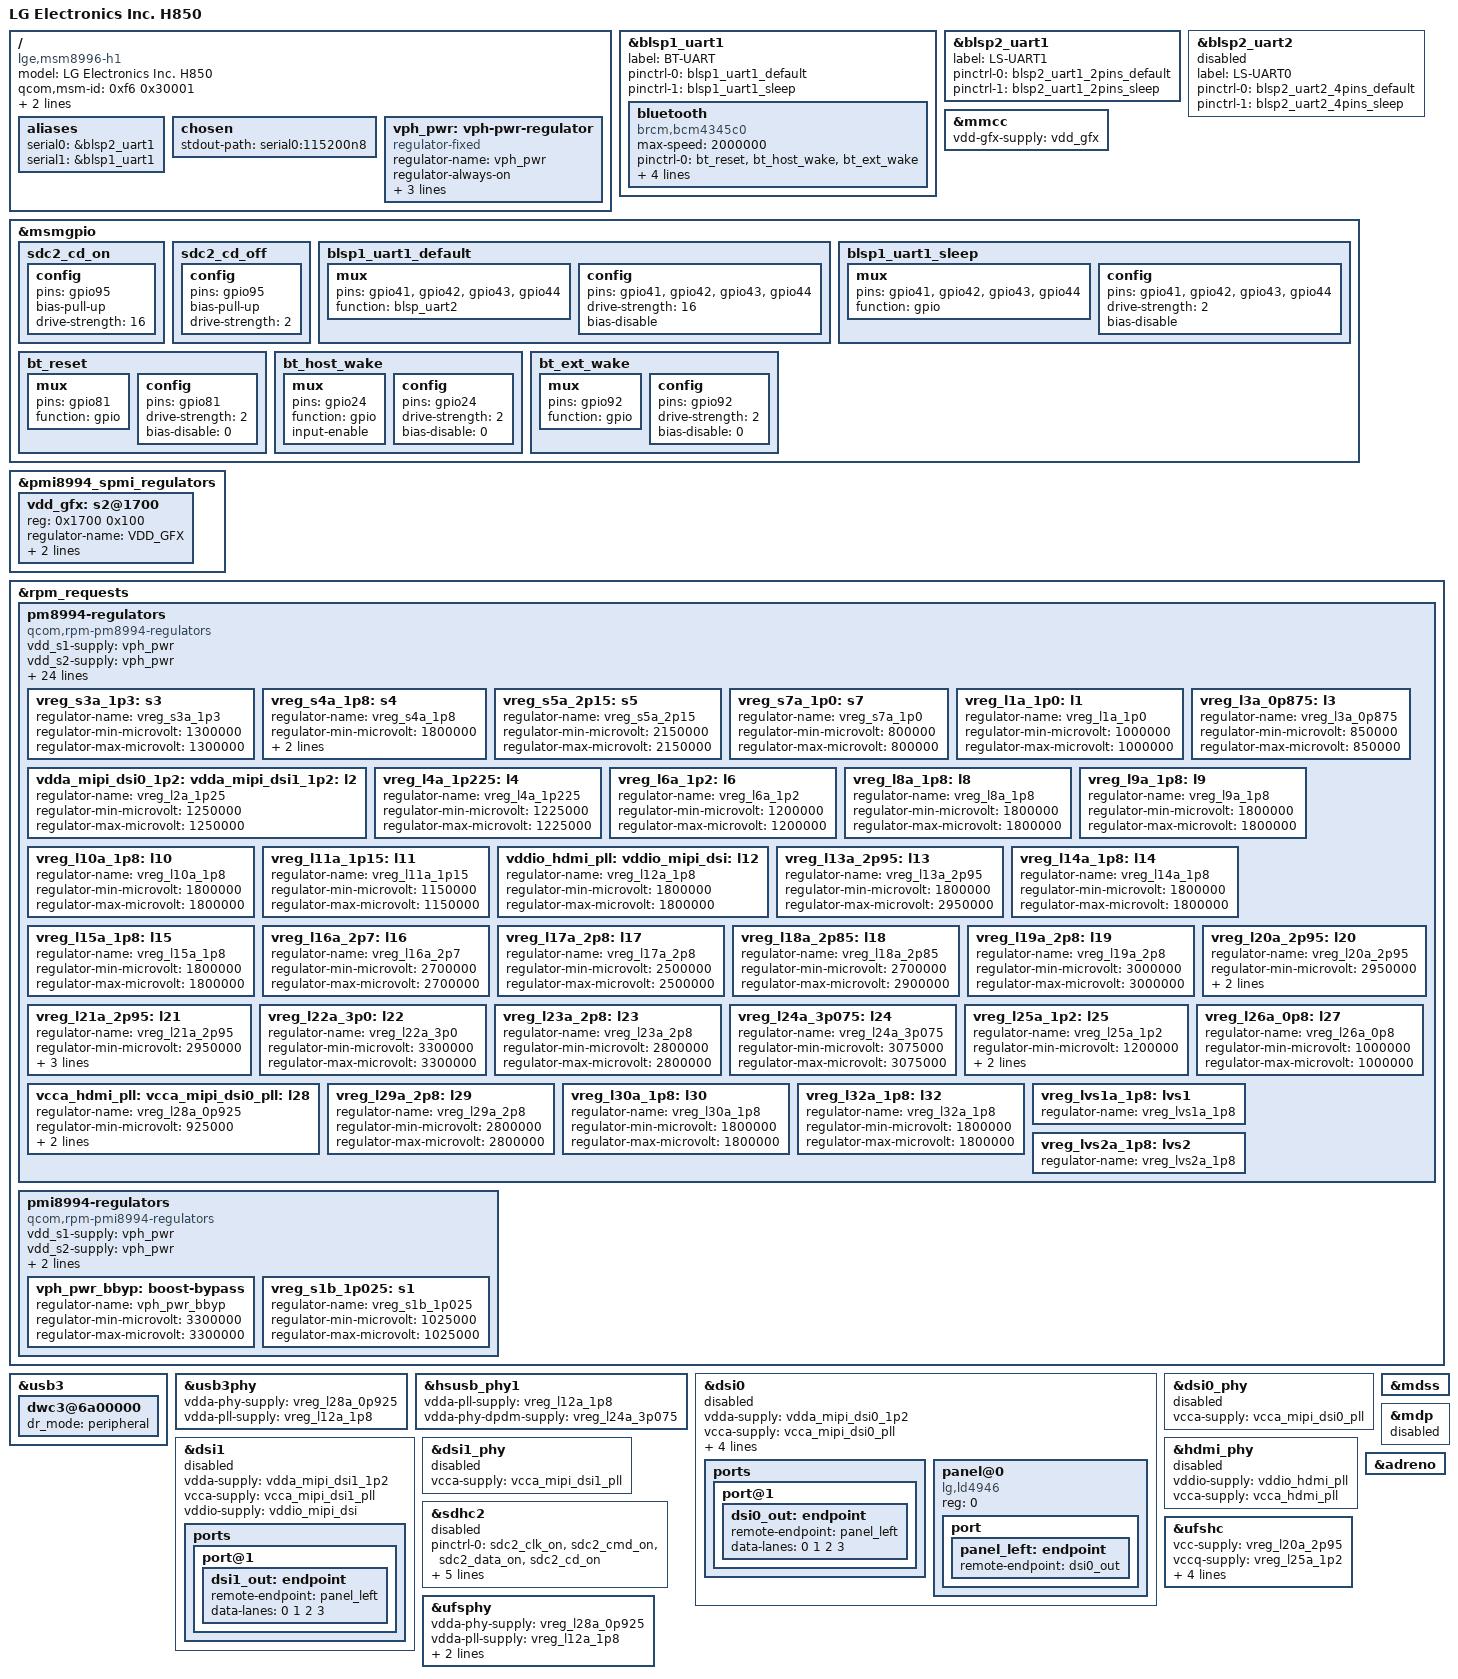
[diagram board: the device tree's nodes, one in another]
// SPDX-License-Identifier: GPL-2.0-only
/*
 * Copyright (c) 2020, The Linux Foundation. All rights reserved.
 */

/dts-v1/;

#include "msm8996.dtsi"
#include "pm8994.dtsi"
#include "pmi8994.dtsi"
#include <dt-bindings/input/input.h>
#include <dt-bindings/gpio/gpio.h>
#include <dt-bindings/pinctrl/qcom,pmic-gpio.h>
// #include <dt-bindings/sound/qcom,q6afe.h>
// #include <dt-bindings/sound/qcom,q6asm.h>

/*
 * GPIO name legend: proper name = the GPIO line is used as GPIO
 *         NC      = not connected (pin out but not routed from the chip to
 *                   anything the board)
 *         "[PER]" = pin is muxed for [peripheral] (not GPIO)
 *         LSEC    = Low Speed External Connector
 *         P HSEC  = Primary High Speed External Connector
 *         S HSEC  = Secondary High Speed External Connector
 *         J14     = Camera Connector
 *         TP      = Test Points
 *
 */

/ {
	model = "LG Electronics Inc. H850";
	compatible = "lge,msm8996-h1", "qcom,apq8096-sbc", "qcom,apq8096";

	qcom,msm-id = <291 0x00030001>;
	qcom,board-id = <0xD08 0>;

	qcom,msm-id=<0xf6 0x30001>;
	qcom,pmic-id=<0x20009 0x10013 0x0 0x0>;
	qcom,board-id=<0xd08 0x0>;


	aliases {
		serial0 = &blsp2_uart1;
		serial1 = &blsp1_uart1;
	};

	chosen {
		stdout-path = "serial0:115200n8";
	};

	vph_pwr: vph-pwr-regulator {
		compatible = "regulator-fixed";
		regulator-name = "vph_pwr";
		regulator-always-on;
		regulator-boot-on;

		regulator-min-microvolt = <3700000>;
		regulator-max-microvolt = <3700000>;
	};

	// panel {
	// 	status = "disabled"
	// 	compatible = "lg,ld4946-dm";

	// 	// pinctrl-names = "default";
	// 	// pinctrl-0 = <&edp_brij_en &edp_brij_irq>;

	// 	// enable-gpios = <&tlmm 102 GPIO_ACTIVE_HIGH>;

	// 	// vdd3-supply = <&reg_panel_vdd3>;
	// 	// vci-supply = <&pm8916_l17>;
	// 	// reset-gpios = <&msmgpio 25 GPIO_ACTIVE_HIGH>;
	// 	// power-supply = <&pp3300_dx_edp>;
	// 	// backlight = <&backlight>;
	// 	// no-hpd;

	// 	// qcom,platform-te-gpio = <&tlmm 10 0>;
	// 	// qcom,platform-reset-gpio = <&tlmm 8 0>;

	// 	no-hpd;

	// 	ports {
	// 		#address-cells = <1>;
	// 		#size-cells = <0>;

	// 		port@0 {
	// 			reg = <0>;
	// 			panel_left: endpoint {
	// 				remote-endpoint = <&dsi0_out>;
	// 			};
	// 		}

	// 		port@1 {
	// 			reg = <1>;
	// 			panel_right: endpoint {
	// 				remote-endpoint = <&dsi1_out>;
	// 			};
	// 		}
	// 	};
	// };
};

&blsp1_uart1 {
	label = "BT-UART";
	status = "okay";
	pinctrl-names = "default", "sleep";
	pinctrl-0 = <&blsp1_uart1_default>;
	pinctrl-1 = <&blsp1_uart1_sleep>;

	bluetooth {
		compatible = "brcm,bcm4345c0";
		max-speed = <2000000>; //<921600>;
		// brcm,bt-pcm-int-params = [01 02 00 01 01];

		pinctrl-names = "default";
		pinctrl-0 = <&bt_reset &bt_host_wake &bt_ext_wake>;

		interrupt-parent = <&msmgpio>;
		interrupts = <24 IRQ_TYPE_EDGE_RISING>;
		interrupt-names = "host-wake";

		shutdown-gpios = <&msmgpio 81 GPIO_ACTIVE_HIGH>;
		device-wakeup-gpios = <&msmgpio 92 GPIO_ACTIVE_HIGH>;
	};
};

&blsp2_uart1 {
	label = "LS-UART1";
	status = "okay";
	pinctrl-names = "default", "sleep";
	pinctrl-0 = <&blsp2_uart1_2pins_default>;
	pinctrl-1 = <&blsp2_uart1_2pins_sleep>;
};

&blsp2_uart2 {
	label = "LS-UART0";
	status = "disabled";
	pinctrl-names = "default", "sleep";
	pinctrl-0 = <&blsp2_uart2_4pins_default>;
	pinctrl-1 = <&blsp2_uart2_4pins_sleep>;
};

&mmcc {
	vdd-gfx-supply = <&vdd_gfx>;
};

&msmgpio {
	sdc2_cd_on: sdc2_cd_on {
		config {
			pins = "gpio95";
			bias-pull-up;
			drive-strength = <16>;	/* 16 MA */
		};
	};

	sdc2_cd_off: sdc2_cd_off {
		config {
			pins = "gpio95";
			bias-pull-up;
			drive-strength = <2>;	/* 2 MA */
		};
	};

	blsp1_uart1_default: blsp1_uart1_default {
		mux {
			pins = "gpio41", "gpio42", "gpio43", "gpio44";
			function = "blsp_uart2";
		};

		config {
			pins = "gpio41", "gpio42", "gpio43", "gpio44";
			drive-strength = <16>;
			bias-disable;
		};
	};

	blsp1_uart1_sleep: blsp1_uart1_sleep {
		mux {
			pins = "gpio41", "gpio42", "gpio43", "gpio44";
			function = "gpio";
		};

		config {
			pins = "gpio41", "gpio42", "gpio43", "gpio44";
			drive-strength = <2>;
			bias-disable;
		};
	};

	bt_reset: bt_reset {
		mux {
			pins = "gpio81";
			function = "gpio";
		};

		config {
			pins = "gpio81";
			drive-strength = <2>;
			bias-disable = <0>;
		};
	};

	bt_host_wake: bt_host_wake {
		mux {
			pins = "gpio24";
			function = "gpio";
			input-enable;
		};

		config {
			pins = "gpio24";
			drive-strength = <2>;
			bias-disable = <0>;
		};
	};

	bt_ext_wake: bt_ext_wake {
		mux {
			pins = "gpio92";
			function = "gpio";
		};

		config {
			pins = "gpio92";
			drive-strength = <2>;
			bias-disable = <0>;
		};
	};
};

// &pm8994_mpps {
// 	gpio-line-names =
// 		"VDDPX_BIAS",
// 		"WIFI_LED",
// 		"NC",
// 		"BT_LED",
// 		"PM_MPP05",
// 		"PM_MPP06",
// 		"PM_MPP07",
// 		"NC";
// };

//&pm8994_spmi_regulators {
//	qcom,saw-reg = <&saw3>;
//	s9 {
//		qcom,saw-slave;
//	};
//	s10 {
//		qcom,saw-slave;
//	};
//	s11 {
//		qcom,saw-leader;
//		regulator-always-on;
//		regulator-min-microvolt = <980000>;
//		regulator-max-microvolt = <980000>;
//	};
//};

&pmi8994_spmi_regulators {
	vdd_gfx: s2@1700 {
		reg = <0x1700 0x100>;
		regulator-name = "VDD_GFX";
		regulator-min-microvolt = <980000>;
		regulator-max-microvolt = <980000>;
	};
};

&rpm_requests {
	pm8994-regulators {
		compatible = "qcom,rpm-pm8994-regulators";

		vdd_s1-supply = <&vph_pwr>;
		vdd_s2-supply = <&vph_pwr>;
		vdd_s3-supply = <&vph_pwr>;
		vdd_s4-supply = <&vph_pwr>;
		vdd_s5-supply = <&vph_pwr>;
		vdd_s6-supply = <&vph_pwr>;
		vdd_s7-supply = <&vph_pwr>;
		vdd_s8-supply = <&vph_pwr>;
		vdd_s9-supply = <&vph_pwr>;
		vdd_s10-supply = <&vph_pwr>;
		vdd_s11-supply = <&vph_pwr>;
		vdd_s12-supply = <&vph_pwr>;
		vdd_l1-supply = <&vreg_s1b_1p025>;
		vdd_l2_l26_l28-supply = <&vreg_s3a_1p3>;
		vdd_l3_l11-supply = <&vreg_s3a_1p3>;
		vdd_l4_l27_l31-supply = <&vreg_s3a_1p3>;
		vdd_l5_l7-supply = <&vreg_s5a_2p15>;
		vdd_l6_l12_l32-supply = <&vreg_s5a_2p15>;
		vdd_l8_l16_l30-supply = <&vph_pwr>;
		vdd_l9_l10_l18_l22-supply = <&vph_pwr_bbyp>;
		vdd_l13_l19_l23_l24-supply = <&vph_pwr_bbyp>;
		vdd_l14_l15-supply = <&vreg_s5a_2p15>;
		vdd_l17_l29-supply = <&vph_pwr_bbyp>;
		vdd_l20_l21-supply = <&vph_pwr_bbyp>;
		vdd_l25-supply = <&vreg_s3a_1p3>;
		vdd_lvs1_lvs2-supply = <&vreg_s4a_1p8>;

		vreg_s3a_1p3: s3 {
			regulator-name = "vreg_s3a_1p3";
			regulator-min-microvolt = <1300000>;
			regulator-max-microvolt = <1300000>;
		};

		/**
		 * 1.8v required on LS expansion
		 * for mezzanine boards
		 */
		vreg_s4a_1p8: s4 {
			regulator-name = "vreg_s4a_1p8";
			regulator-min-microvolt = <1800000>;
			regulator-max-microvolt = <1800000>;
			regulator-always-on;
		};
		vreg_s5a_2p15: s5 {
			regulator-name = "vreg_s5a_2p15";
			regulator-min-microvolt = <2150000>;
			regulator-max-microvolt = <2150000>;
		};
		vreg_s7a_1p0: s7 {
			regulator-name = "vreg_s7a_1p0";
			regulator-min-microvolt = <800000>;
			regulator-max-microvolt = <800000>;
		};

		vreg_l1a_1p0: l1 {
			regulator-name = "vreg_l1a_1p0";
			regulator-min-microvolt = <1000000>;
			regulator-max-microvolt = <1000000>;
		};
		vdda_mipi_dsi0_1p2:
		vdda_mipi_dsi1_1p2:
		vreg_l2a_1p25: l2 {
			regulator-name = "vreg_l2a_1p25";
			regulator-min-microvolt = <1250000>;
			regulator-max-microvolt = <1250000>;
		};
		vreg_l3a_0p875: l3 {
			regulator-name = "vreg_l3a_0p875";
			regulator-min-microvolt = <850000>;
			regulator-max-microvolt = <850000>;
		};
		vreg_l4a_1p225: l4 {
			regulator-name = "vreg_l4a_1p225";
			regulator-min-microvolt = <1225000>;
			regulator-max-microvolt = <1225000>;
		};
		vreg_l6a_1p2: l6 {
			regulator-name = "vreg_l6a_1p2";
			regulator-min-microvolt = <1200000>;
			regulator-max-microvolt = <1200000>;
		};
		vreg_l8a_1p8: l8 {
			regulator-name = "vreg_l8a_1p8";
			regulator-min-microvolt = <1800000>;
			regulator-max-microvolt = <1800000>;
		};
		vreg_l9a_1p8: l9 {
			regulator-name = "vreg_l9a_1p8";
			regulator-min-microvolt = <1800000>;
			regulator-max-microvolt = <1800000>;
		};
		vreg_l10a_1p8: l10 {
			regulator-name = "vreg_l10a_1p8";
			regulator-min-microvolt = <1800000>;
			regulator-max-microvolt = <1800000>;
		};
		vreg_l11a_1p15: l11 {
			regulator-name = "vreg_l11a_1p15";
			regulator-min-microvolt = <1150000>;
			regulator-max-microvolt = <1150000>;
		};
		vddio_hdmi_pll:
		vddio_mipi_dsi:
		vreg_l12a_1p8: l12 {
			regulator-name = "vreg_l12a_1p8";
			regulator-min-microvolt = <1800000>;
			regulator-max-microvolt = <1800000>;
		};
		vreg_l13a_2p95: l13 {
			regulator-name = "vreg_l13a_2p95";
			regulator-min-microvolt = <1800000>;
			regulator-max-microvolt = <2950000>;
		};
		vreg_l14a_1p8: l14 {
			regulator-name = "vreg_l14a_1p8";
			regulator-min-microvolt = <1800000>;
			regulator-max-microvolt = <1800000>;
		};
		vreg_l15a_1p8: l15 {
			regulator-name = "vreg_l15a_1p8";
			regulator-min-microvolt = <1800000>;
			regulator-max-microvolt = <1800000>;
		};
		vreg_l16a_2p7: l16 {
			regulator-name = "vreg_l16a_2p7";
			regulator-min-microvolt = <2700000>;
			regulator-max-microvolt = <2700000>;
		};
		vreg_l17a_2p8: l17 {
			regulator-name = "vreg_l17a_2p8";
			regulator-min-microvolt = <2500000>;
			regulator-max-microvolt = <2500000>;
		};
		vreg_l18a_2p85: l18 {
			regulator-name = "vreg_l18a_2p85";
			regulator-min-microvolt = <2700000>;
			regulator-max-microvolt = <2900000>;
		};
		vreg_l19a_2p8: l19 {
			regulator-name = "vreg_l19a_2p8";
			regulator-min-microvolt = <3000000>;
			regulator-max-microvolt = <3000000>;
		};
		vreg_l20a_2p95: l20 {
			regulator-name = "vreg_l20a_2p95";
			regulator-min-microvolt = <2950000>;
			regulator-max-microvolt = <2950000>;
			regulator-allow-set-load;
		};
		vreg_l21a_2p95: l21 {
			regulator-name = "vreg_l21a_2p95";
			regulator-min-microvolt = <2950000>;
			regulator-max-microvolt = <2950000>;
			regulator-allow-set-load;
			regulator-system-load = <200000>;
		};
		vreg_l22a_3p0: l22 {
			regulator-name = "vreg_l22a_3p0";
			regulator-min-microvolt = <3300000>;
			regulator-max-microvolt = <3300000>;
		};
		vreg_l23a_2p8: l23 {
			regulator-name = "vreg_l23a_2p8";
			regulator-min-microvolt = <2800000>;
			regulator-max-microvolt = <2800000>;
		};
		vreg_l24a_3p075: l24 {
			regulator-name = "vreg_l24a_3p075";
			regulator-min-microvolt = <3075000>;
			regulator-max-microvolt = <3075000>;
		};
		vreg_l25a_1p2: l25 {
			regulator-name = "vreg_l25a_1p2";
			regulator-min-microvolt = <1200000>;
			regulator-max-microvolt = <1200000>;
			regulator-allow-set-load;
		};
		vreg_l26a_0p8: l27 {
			regulator-name = "vreg_l26a_0p8";
			regulator-min-microvolt = <1000000>;
			regulator-max-microvolt = <1000000>;
		};
		vcca_hdmi_pll:
		vcca_mipi_dsi0_pll:
		vcca_mipi_dsi1_pll:
		vreg_l28a_0p925: l28 {
			regulator-name = "vreg_l28a_0p925";
			regulator-min-microvolt = <925000>;
			regulator-max-microvolt = <925000>;
			regulator-allow-set-load;
		};
		vreg_l29a_2p8: l29 {
			regulator-name = "vreg_l29a_2p8";
			regulator-min-microvolt = <2800000>;
			regulator-max-microvolt = <2800000>;
		};
		vreg_l30a_1p8: l30 {
			regulator-name = "vreg_l30a_1p8";
			regulator-min-microvolt = <1800000>;
			regulator-max-microvolt = <1800000>;
		};
		vreg_l32a_1p8: l32 {
			regulator-name = "vreg_l32a_1p8";
			regulator-min-microvolt = <1800000>;
			regulator-max-microvolt = <1800000>;
		};

		vreg_lvs1a_1p8: lvs1 {
			regulator-name = "vreg_lvs1a_1p8";
		};

		vreg_lvs2a_1p8: lvs2 {
			regulator-name = "vreg_lvs2a_1p8";
		};
	};

	pmi8994-regulators {
		compatible = "qcom,rpm-pmi8994-regulators";

		vdd_s1-supply = <&vph_pwr>;
		vdd_s2-supply = <&vph_pwr>;
		vdd_s3-supply = <&vph_pwr>;
		vdd_bst_byp-supply = <&vph_pwr>;

		vph_pwr_bbyp: boost-bypass {
			regulator-name = "vph_pwr_bbyp";
			regulator-min-microvolt = <3300000>;
			regulator-max-microvolt = <3300000>;
		};

		vreg_s1b_1p025: s1 {
			regulator-name = "vreg_s1b_1p025";
			regulator-min-microvolt = <1025000>;
			regulator-max-microvolt = <1025000>;
		};
	};
};

&usb3 {
	status = "okay";
	// extcon = <&usb3_id>;

	dwc3@6a00000 {
		// extcon = <&usb3_id>;
		dr_mode = "peripheral"; // Force to gadget until we have Type-C hooked up
	};
};

&usb3phy {
	status = "okay";

	vdda-phy-supply = <&vreg_l28a_0p925>;
	vdda-pll-supply = <&vreg_l12a_1p8>;
};

// This one is used for usb-c together with usb3phy
&hsusb_phy1 {
	status = "okay";

	vdda-pll-supply = <&vreg_l12a_1p8>;
	vdda-phy-dpdm-supply = <&vreg_l24a_3p075>;
};

// Almost definitely not used
/*
&hsusb_phy2 {
	status = "okay";

	vdda-pll-supply = <&vreg_l12a_1p8>;
	vdda-phy-dpdm-supply = <&vreg_l24a_3p075>;
};*/

&dsi0 {
	status = "disabled";
	vdda-supply = <&vdda_mipi_dsi0_1p2>;
	vcca-supply = <&vcca_mipi_dsi0_pll>;
	// vdd-supply = <&vdda_mipi_dsi0_1p2>;
	vddio-supply = <&vddio_mipi_dsi>;

	// lge,extra-gpio-names = "vddio", "vpnl";

	// lge,gpio-vddio = <&tlmm 79 0>;
	// lge,gpio-vpnl = <&tlmm 94 0>;

	qcom,dual-dsi-mode;
	qcom,master-dsi;
	qcom,sync-dual-dsi;

	#address-cells = <1>;
	#size-cells = <0>;

	ports {
		port@1 {
			dsi0_out: endpoint {
				remote-endpoint = <&panel_left>;
				data-lanes = <0 1 2 3>;
			};
		};
	};

	panel@0 {
		reg = <0>;
		compatible = "lg,ld4946";

		// vdd3-supply = <&reg_panel_vdd3>;
		// vci-supply = <&pm8916_l17>;
		// reset-gpios = <&msmgpio 25 GPIO_ACTIVE_HIGH>;
		// power-supply = <&pp3300_dx_edp>;
		// backlight = <&backlight>;
		// no-hpd;

		// qcom,platform-te-gpio = <&tlmm 10 0>;
		// qcom,platform-reset-gpio = <&tlmm 8 0>;

		// ports {
		// 	#address-cells = <1>;
		// 	#size-cells = <0>;

		port {
			panel_left: endpoint {
				remote-endpoint = <&dsi0_out>;
			};
		};
	};
};

&dsi0_phy {
	status = "disabled";
	vcca-supply = <&vcca_mipi_dsi0_pll>;
};

&dsi1 {
	status = "disabled";
	vdda-supply = <&vdda_mipi_dsi1_1p2>;
	vcca-supply = <&vcca_mipi_dsi1_pll>;
	vddio-supply = <&vddio_mipi_dsi>;

	// qcom,dual-dsi-mode;
	// qcom,master-dsi;
	// qcom,sync-dual-dsi;

	// #address-cells = <1>;
	// #size-cells = <0>;

	ports {
		port@1 {
			dsi1_out: endpoint {
				remote-endpoint = <&panel_left>;
				data-lanes = <0 1 2 3>;
			};
		};
	};

	// panel@0 {
	// 	reg = <0>;
	// 	// compatible = "lg,ld4946";

	// 	// vdd3-supply = <&reg_panel_vdd3>;
	// 	// vci-supply = <&pm8916_l17>;
	// 	// reset-gpios = <&msmgpio 25 GPIO_ACTIVE_HIGH>;
	// 	// power-supply = <&pp3300_dx_edp>;
	// 	// backlight = <&backlight>;
	// 	// no-hpd;

	// 	// qcom,platform-te-gpio = <&tlmm 10 0>;
	// 	// qcom,platform-reset-gpio = <&tlmm 8 0>;

	// 	// ports {
	// 	// 	#address-cells = <1>;
	// 	// 	#size-cells = <0>;

	// 	port {
	// 		panel_right: endpoint {
	// 			remote-endpoint = <&dsi1_out>;
	// 		};
	// 	};
	// };
};

&dsi1_phy {
	status = "disabled";
	vcca-supply = <&vcca_mipi_dsi1_pll>;
};

&hdmi_phy {
	status = "disabled";
	vddio-supply = <&vddio_hdmi_pll>;
	vcca-supply = <&vcca_hdmi_pll>;
};

// might be not needed - not disabled by default
&mdss {
	status = "okay";
};

// might be not needed - not disabled by default
&mdp {
	status = "disabled";
};

&adreno {
	status = "okay";
};

&sdhc2 {
	/* External SD card */
	status = "disabled"; // irq is not received ...

	// bus-width = <4>; // already set in SoC dtsi

	pinctrl-names = "default", "sleep";
	pinctrl-0 = <&sdc2_clk_on &sdc2_cmd_on &sdc2_data_on &sdc2_cd_on>;
	pinctrl-1 = <&sdc2_clk_off &sdc2_cmd_off &sdc2_data_off &sdc2_cd_off>;

	cd-gpios = <&msmgpio 95 0x0>;

	vmmc-supply = <&vreg_l21a_2p95>;
	vqmmc-supply = <&vreg_l13a_2p95>;
};

&ufshc {
	status = "okay";

	// reset-gpios = <&tlmm 150 GPIO_ACTIVE_LOW>;

	vcc-supply = <&vreg_l20a_2p95>;
	vccq-supply = <&vreg_l25a_1p2>;
	vccq2-supply = <&vreg_s4a_1p8>;

	vcc-max-microamp = <600000>;
	vccq-max-microamp = <450000>;
	vccq2-max-microamp = <450000>;
};

&ufsphy {
	status = "okay";

	vdda-phy-supply = <&vreg_l28a_0p925>;
	vdda-pll-supply = <&vreg_l12a_1p8>;

	vdda-phy-max-microamp = <18380>;
	vdda-pll-max-microamp = <9440>;
};
